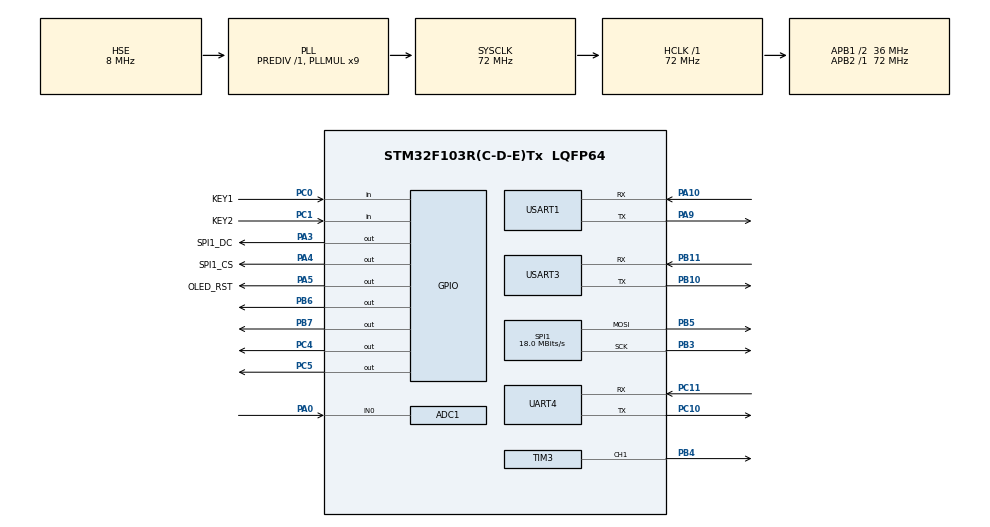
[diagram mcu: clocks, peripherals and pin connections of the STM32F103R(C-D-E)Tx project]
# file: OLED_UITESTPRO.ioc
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ADC1.Channel-0\#ChannelRegularConversion=ADC_CHANNEL_0
ADC1.NbrOfConversionFlag=1
ADC1.Rank-0\#ChannelRegularConversion=1
ADC1.SamplingTime-0\#ChannelRegularConversion=ADC_SAMPLETIME_1CYCLE_5
ADC1.master=1
Dma.Request0=SPI1_TX
Dma.Request1=USART1_RX
Dma.Request2=TIM3_CH1/TRIG
Dma.SPI1_TX.0.Direction=DMA_MEMORY_TO_PERIPH
Dma.SPI1_TX.0.Instance=DMA1_Channel3
Dma.SPI1_TX.0.MemDataAlignment=DMA_MDATAALIGN_BYTE
Dma.SPI1_TX.0.MemInc=DMA_MINC_ENABLE
Dma.SPI1_TX.0.Mode=DMA_NORMAL
Dma.SPI1_TX.0.PeriphDataAlignment=DMA_PDATAALIGN_BYTE
Dma.SPI1_TX.0.PeriphInc=DMA_PINC_DISABLE
Dma.SPI1_TX.0.Priority=DMA_PRIORITY_LOW
Dma.TIM3_CH1/TRIG.2.Direction=DMA_MEMORY_TO_PERIPH
Dma.TIM3_CH1/TRIG.2.Instance=DMA1_Channel6
Dma.TIM3_CH1/TRIG.2.MemDataAlignment=DMA_MDATAALIGN_HALFWORD
Dma.TIM3_CH1/TRIG.2.MemInc=DMA_MINC_ENABLE
Dma.TIM3_CH1/TRIG.2.Mode=DMA_NORMAL
Dma.TIM3_CH1/TRIG.2.PeriphDataAlignment=DMA_PDATAALIGN_HALFWORD
Dma.TIM3_CH1/TRIG.2.PeriphInc=DMA_PINC_DISABLE
Dma.TIM3_CH1/TRIG.2.Priority=DMA_PRIORITY_LOW
Dma.USART1_RX.1.Direction=DMA_PERIPH_TO_MEMORY
Dma.USART1_RX.1.Instance=DMA1_Channel5
Dma.USART1_RX.1.MemDataAlignment=DMA_MDATAALIGN_BYTE
Dma.USART1_RX.1.MemInc=DMA_MINC_ENABLE
Dma.USART1_RX.1.Mode=DMA_NORMAL
Dma.USART1_RX.1.PeriphDataAlignment=DMA_PDATAALIGN_BYTE
Dma.USART1_RX.1.PeriphInc=DMA_PINC_DISABLE
Dma.USART1_RX.1.Priority=DMA_PRIORITY_LOW
Mcu.Family=STM32F1
Mcu.Name=STM32F103R(C-D-E)Tx
Mcu.Package=LQFP64
NVIC.ADC1_2_IRQn=true\:0\:0\:false\:false\:true\:true\:true\:true
NVIC.DMA1_Channel3_IRQn=true\:0\:0\:false\:false\:true\:false\:true\:true
NVIC.DMA1_Channel5_IRQn=true\:0\:0\:false\:false\:true\:false\:true\:true
NVIC.DMA1_Channel6_IRQn=true\:0\:0\:true\:false\:true\:false\:true\:true
NVIC.PriorityGroup=NVIC_PRIORITYGROUP_4
NVIC.RTC_Alarm_IRQn=true\:1\:0\:true\:false\:true\:true\:true\:true
NVIC.RTC_IRQn=true\:0\:0\:false\:false\:true\:true\:true\:true
NVIC.SPI1_IRQn=true\:1\:0\:true\:false\:true\:true\:true\:true
NVIC.TIM1_UP_IRQn=true\:0\:0\:true\:false\:true\:true\:true\:true
NVIC.TIM2_IRQn=true\:1\:0\:true\:false\:true\:true\:true\:true
NVIC.TIM6_IRQn=true\:1\:0\:true\:false\:true\:true\:true\:true
NVIC.TIM7_IRQn=true\:1\:0\:true\:false\:true\:true\:true\:true
NVIC.USART1_IRQn=true\:1\:0\:true\:false\:true\:true\:true\:true
NVIC.USART3_IRQn=true\:1\:0\:true\:false\:true\:true\:true\:true
PA0-WKUP.Signal=ADCx_IN0
PA10.Mode=Asynchronous
PA10.Signal=USART1_RX
PA13.Mode=Serial_Wire
PA13.Signal=SYS_JTMS-SWDIO
PA14.Mode=Serial_Wire
PA14.Signal=SYS_JTCK-SWCLK
PA3.GPIO_Label=SPI1_DC
PA3.GPIO_Speed=GPIO_SPEED_FREQ_HIGH
PA3.Signal=GPIO_Output
PA4.GPIO_Label=SPI1_CS
PA4.GPIO_Speed=GPIO_SPEED_FREQ_HIGH
PA4.Signal=GPIO_Output
PA5.GPIO_Label=OLED_RST
PA5.GPIO_Speed=GPIO_SPEED_FREQ_HIGH
PA5.Signal=GPIO_Output
PA9.Mode=Asynchronous
PA9.Signal=USART1_TX
PB10.Mode=Asynchronous
PB10.Signal=USART3_TX
PB11.Mode=Asynchronous
PB11.Signal=USART3_RX
PB3.Mode=TX_Only_Simplex_Unidirect_Master
PB3.Signal=SPI1_SCK
PB4.GPIO_ModeDefaultPP=GPIO_MODE_AF_OD
PB4.GPIO_Speed=GPIO_SPEED_FREQ_HIGH
PB4.Signal=S_TIM3_CH1
PB5.Mode=TX_Only_Simplex_Unidirect_Master
PB5.Signal=SPI1_MOSI
PB6.GPIO_PuPd=GPIO_PULLUP
PB6.GPIO_Speed=GPIO_SPEED_FREQ_HIGH
PB6.Signal=GPIO_Output
PB7.GPIO_PuPd=GPIO_PULLUP
PB7.GPIO_Speed=GPIO_SPEED_FREQ_HIGH
PB7.Signal=GPIO_Output
PC0.GPIO_Label=KEY1
PC0.GPIO_PuPd=GPIO_PULLUP
PC0.Signal=GPIO_Input
PC1.GPIO_Label=KEY2
PC1.GPIO_PuPd=GPIO_PULLUP
PC1.Signal=GPIO_Input
PC10.Mode=Asynchronous
PC10.Signal=UART4_TX
PC11.Mode=Asynchronous
PC11.Signal=UART4_RX
PC14-OSC32_IN.Mode=LSE-External-Oscillator
PC14-OSC32_IN.Signal=RCC_OSC32_IN
PC15-OSC32_OUT.Mode=LSE-External-Oscillator
PC15-OSC32_OUT.Signal=RCC_OSC32_OUT
PC4.GPIO_PuPd=GPIO_PULLUP
PC4.PinState=GPIO_PIN_SET
PC4.Signal=GPIO_Output
PC5.GPIO_ModeDefaultOutputPP=GPIO_MODE_OUTPUT_PP
PC5.GPIO_PuPd=GPIO_PULLUP
PC5.PinState=GPIO_PIN_SET
PC5.Signal=GPIO_Output
PD0-OSC_IN.Mode=HSE-External-Oscillator
PD0-OSC_IN.Signal=RCC_OSC_IN
PD1-OSC_OUT.Mode=HSE-External-Oscillator
PD1-OSC_OUT.Signal=RCC_OSC_OUT
ProjectManager.HeapSize=0x2000
ProjectManager.StackSize=0x4000
ProjectManager.TargetToolchain=CMake
RCC.ADCPresc=RCC_ADCPCLK2_DIV6
RCC.AHBFreq_Value=72000000
RCC.APB1CLKDivider=RCC_HCLK_DIV2
RCC.APB1Freq_Value=36000000
RCC.APB1TimFreq_Value=72000000
RCC.APB2Freq_Value=72000000
RCC.APB2TimFreq_Value=72000000
RCC.HCLKFreq_Value=72000000
RCC.PLLMUL=RCC_PLL_MUL9
RCC.PLLSourceVirtual=RCC_PLLSOURCE_HSE
RCC.RTCClockSelection=RCC_RTCCLKSOURCE_LSE
RCC.SYSCLKFreq_VALUE=72000000
RCC.SYSCLKSource=RCC_SYSCLKSOURCE_PLLCLK
RCC.USBFreq_Value=72000000
SH.ADCx_IN0.0=ADC1_IN0,IN0
SH.S_TIM3_CH1.0=TIM3_CH1,PWM Generation1 CH1
SPI1.BaudRatePrescaler=SPI_BAUDRATEPRESCALER_4
SPI1.CLKPhase=SPI_PHASE_2EDGE
SPI1.CLKPolarity=SPI_POLARITY_HIGH
SPI1.CalculateBaudRate=18.0 MBits/s
SPI1.Direction=SPI_DIRECTION_2LINES
SPI1.FirstBit=SPI_FIRSTBIT_MSB
SPI1.Mode=SPI_MODE_MASTER
SPI1.VirtualType=VM_MASTER
TIM1.Period=1000-1
TIM1.Prescaler=7200-1
TIM2.Period=1000-1
TIM2.Prescaler=7200-1
TIM3.Channel-PWM\ Generation1\ CH1=TIM_CHANNEL_1
TIM3.Period=90-1
TIM6.Prescaler=72-1
TIM7.Period=10000-1
TIM7.Prescaler=7200-1
UART4.VirtualMode=Asynchronous
USART1.VirtualMode=VM_ASYNC
USART3.VirtualMode=VM_ASYNC
VP_RTC_VS_RTC_Activate.Mode=RTC_Enabled
VP_RTC_VS_RTC_Calendar.Mode=RTC_Calendar
VP_TIM1_VS_ClockSourceINT.Mode=Internal
VP_TIM2_VS_ClockSourceINT.Mode=Internal
VP_TIM3_VS_ClockSourceINT.Mode=Internal
VP_TIM6_VS_ClockSourceINT.Mode=Enable_Timer
VP_TIM7_VS_ClockSourceINT.Mode=Enable_Timer
board=custom

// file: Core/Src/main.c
/* USER CODE BEGIN Header */
/**
  ******************************************************************************
  * @file           : main.c
  * @brief          : Main program body
  ******************************************************************************
  * @attention
  *
  * Copyright (c) 2025 STMicroelectronics.
  * All rights reserved.
  *
  * This software is licensed under terms that can be found in the LICENSE file
  * in the root directory of this software component.
  * If no LICENSE file comes with this software, it is provided AS-IS.
  *
  ******************************************************************************
  */
/* USER CODE END Header */
#include "main.h"
#include "adc.h"
#include "dma.h"
#include "rtc.h"
#include "spi.h"
#include "tim.h"
#include "usart.h"
#include "gpio.h"

/* USER CODE BEGIN Includes */
#include "astra_rocket.h"

/* USER CODE END Includes */

void SystemClock_Config(void);

int main(void)
{

  /* MCU Configuration--------------------------------------------------------*/

  /* Reset of all peripherals, Initializes the Flash interface and the Systick. */
  HAL_Init();

  /* Configure the system clock */
  SystemClock_Config();

  /* Initialize all configured peripherals */
  MX_GPIO_Init();
  MX_DMA_Init();
  MX_SPI1_Init();
  MX_ADC1_Init();
  MX_TIM6_Init();
  MX_USART1_UART_Init();
  MX_TIM3_Init();
  MX_RTC_Init();
  MX_USART3_UART_Init();
  MX_TIM2_Init();
  MX_TIM7_Init();
  MX_TIM1_Init();
  MX_UART4_Init();
  /* USER CODE BEGIN 2 */
  astraCoreInit();
  CppMain();
  /* USER CODE END 2 */

  /* Infinite loop */
  while (1)
  {

  }
}

void SystemClock_Config(void)
{
  RCC_OscInitTypeDef RCC_OscInitStruct = {0};
  RCC_ClkInitTypeDef RCC_ClkInitStruct = {0};
  RCC_PeriphCLKInitTypeDef PeriphClkInit = {0};

  /** Initializes the RCC Oscillators according to the specified parameters
  * in the RCC_OscInitTypeDef structure.
  */
  RCC_OscInitStruct.OscillatorType = RCC_OSCILLATORTYPE_HSE|RCC_OSCILLATORTYPE_LSE;
  RCC_OscInitStruct.HSEState = RCC_HSE_ON;
  RCC_OscInitStruct.HSEPredivValue = RCC_HSE_PREDIV_DIV1;
  RCC_OscInitStruct.LSEState = RCC_LSE_ON;
  RCC_OscInitStruct.HSIState = RCC_HSI_ON;
  RCC_OscInitStruct.PLL.PLLState = RCC_PLL_ON;
  RCC_OscInitStruct.PLL.PLLSource = RCC_PLLSOURCE_HSE;
  RCC_OscInitStruct.PLL.PLLMUL = RCC_PLL_MUL9;
  if (HAL_RCC_OscConfig(&RCC_OscInitStruct) != HAL_OK)
  {
    Error_Handler();
  }

  /** Initializes the CPU, AHB and APB buses clocks
  */
  RCC_ClkInitStruct.ClockType = RCC_CLOCKTYPE_HCLK|RCC_CLOCKTYPE_SYSCLK
                              |RCC_CLOCKTYPE_PCLK1|RCC_CLOCKTYPE_PCLK2;
  RCC_ClkInitStruct.SYSCLKSource = RCC_SYSCLKSOURCE_PLLCLK;
  RCC_ClkInitStruct.AHBCLKDivider = RCC_SYSCLK_DIV1;
  RCC_ClkInitStruct.APB1CLKDivider = RCC_HCLK_DIV2;
  RCC_ClkInitStruct.APB2CLKDivider = RCC_HCLK_DIV1;

  if (HAL_RCC_ClockConfig(&RCC_ClkInitStruct, FLASH_LATENCY_2) != HAL_OK)
  {
    Error_Handler();
  }
  PeriphClkInit.PeriphClockSelection = RCC_PERIPHCLK_RTC|RCC_PERIPHCLK_ADC;
  PeriphClkInit.RTCClockSelection = RCC_RTCCLKSOURCE_LSE;
  PeriphClkInit.AdcClockSelection = RCC_ADCPCLK2_DIV6;
  if (HAL_RCCEx_PeriphCLKConfig(&PeriphClkInit) != HAL_OK)
  {
    Error_Handler();
  }
}

void Error_Handler(void)
{
  __disable_irq();
  while (1)
  {
  }
}
